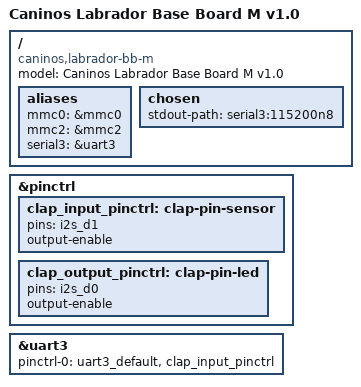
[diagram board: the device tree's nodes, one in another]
// SPDX-License-Identifier: (GPL-2.0+ OR MIT)
/*
 * Copyright (c) 2019-2020 Matheus Castello
 */

/dts-v1/;

#include "owl-s500-labrador-v2.dtsi"

/ {
	compatible = "caninos,labrador-bb-m", "caninos,labrador", "actions,s500";
	model = "Caninos Labrador Base Board M v1.0";

	aliases {
		mmc0 = &mmc0;
		mmc2 = &mmc2;
		serial3 = &uart3;
	};

	chosen {
		stdout-path = "serial3:115200n8";
	};

	/*button-tester {
		compatible = "texugo,button";
		pinctrl-names = "default";
		pinctrl-0 = <&clap_input_pinctrl &clap_output_pinctrl>;
		interrupt-parent = <&pinctrl>;
		interrupts = <24 IRQ_TYPE_EDGE_BOTH>;
		label = "led";
		led-gpios = <&gpio 23 GPIO_ACTIVE_HIGH>;
	};*/
};

&pinctrl {
	clap_input_pinctrl: clap-pin-sensor {
		pins = "i2s_d1";
		output-enable;
	};

	clap_output_pinctrl: clap-pin-led {
		pins = "i2s_d0";
		output-enable;
	};
};

&uart3 {
	pinctrl-names = "default";
	pinctrl-0 = <&uart3_default &clap_input_pinctrl>;
	status = "okay";
};

/* uSD */
/*&mmc0 {
	status = "okay";
	pinctrl-names = "default";
	pinctrl-0 = <&mmc0_default>;
	no-sdio;
	no-mmc;
	no-1-8-v;
	cd-gpios = <&pinctrl 120 GPIO_ACTIVE_LOW>;
	bus-width = <4>;
	vmmc-supply = <&sd_vcc>;
	vqmmc-supply = <&sd_vcc>;
};*/

/* eMMC */
/*&mmc2 {
	status = "okay";
	pinctrl-names = "default";
	pinctrl-0 = <&mmc2_default>;
	no-sdio;
	no-sd;
	non-removable;
	bus-width = <8>;
	vmmc-supply = <&vcc_3v1>;
};*/
